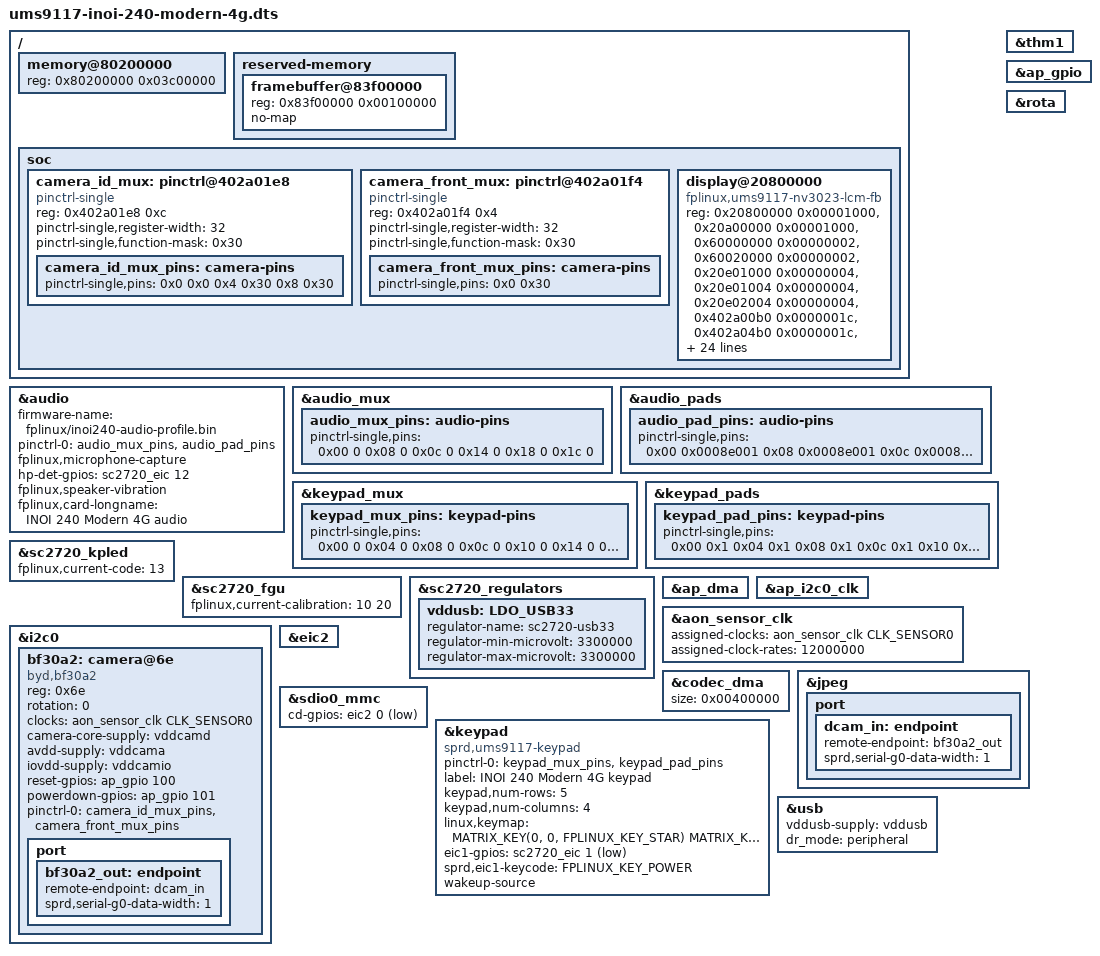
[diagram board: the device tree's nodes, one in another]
// SPDX-License-Identifier: GPL-2.0-only
/dts-v1/;

#include <dt-bindings/input/input.h>
#include <dt-bindings/input/fplinux-keypad.h>
#include <dt-bindings/gpio/gpio.h>
#include <dt-bindings/leds/common.h>
#include "ums9117.dtsi"
#include "ums9117-sc2720.dtsi"
#include "ums9117-musb-cold.dtsi"
#include "fplinux-inoi-240-modern-4g-identity.dtsi"
#include "inoi-240-modern-4g-nand-readonly.dtsi"
#include "inoi-240-modern-4g-bluetooth.dtsi"

/ {
	memory@80200000 {
		device_type = "memory";
		reg = <0x80200000 0x03c00000>;
	};

	reserved-memory {
		#address-cells = <1>;
		#size-cells = <1>;
		ranges;

		framebuffer@83f00000 {
			reg = <0x83f00000 0x00100000>;
			no-map;
		};
	};

	soc {
		camera_id_mux: pinctrl@402a01e8 {
			compatible = "pinctrl-single";
			reg = <0x402a01e8 0xc>;
			#pinctrl-cells = <1>;
			pinctrl-single,register-width = <32>;
			pinctrl-single,function-mask = <0x30>;

			camera_id_mux_pins: camera-pins {
				pinctrl-single,pins = <0x0 0x0 0x4 0x30 0x8 0x30>;
			};
		};

		camera_front_mux: pinctrl@402a01f4 {
			compatible = "pinctrl-single";
			reg = <0x402a01f4 0x4>;
			#pinctrl-cells = <1>;
			pinctrl-single,register-width = <32>;
			pinctrl-single,function-mask = <0x30>;

			camera_front_mux_pins: camera-pins {
				pinctrl-single,pins = <0x0 0x30>;
			};
		};

		display@20800000 {
			compatible = "fplinux,ums9117-nv3023-lcm-fb";
			reg = <0x20800000 0x00001000>,
			      <0x20a00000 0x00001000>,
			      <0x60000000 0x00000002>,
			      <0x60020000 0x00000002>,
			      <0x20e01000 0x00000004>,
			      <0x20e01004 0x00000004>,
			      <0x20e02004 0x00000004>,
			      <0x402a00b0 0x0000001c>,
			      <0x402a04b0 0x0000001c>,
			      <0x402a01f8 0x00000028>,
			      <0x402a05f8 0x00000028>;
			reg-names = "lcdc", "lcm", "lcm-command", "lcm-data",
				    "ap-ahb-gate-set", "ap-ahb-reset-set",
				    "ap-ahb-reset-clear", "pinmux", "pinconf",
				    "pinmux-data", "pinconf-data";
			interrupts = <GIC_SPI 19 IRQ_TYPE_LEVEL_HIGH>;
			interrupt-names = "lcdc-done";
			sprd,aon-apb = <&aon_apb>;
			sprd,pmic = <&sc2720_pmic>;
			memory-region = <&codec_dma>;
			/* fpdoom cmd3025_inoi MCU timing at the 128 MHz AHB clock. */
			sprd,dbi-timing-ns = <50 55 110 20 70 35>;
			/* LCM control pins. */
			sprd,pinmux-offsets = <
				0x000 0x004 0x008 0x00c 0x010 0x014 0x018
			>;
			sprd,pinmux-values = <
				0 0 0x10 0x10 0x10 0x10 0x10
			>;
			sprd,pinconf-offsets = <
				0x000 0x004 0x008 0x00c 0x010 0x014 0x018
			>;
			sprd,pinconf-values = <
				0x00182001 0x00182046 0x00182001
				0x00182004 0x00182004 0x00182004 0x00182004
			>;
			/* Ten DBI data pins, separate from the intervening peripherals. */
			sprd,pinmux-data-offsets = <
				0x00 0x04 0x08 0x0c 0x10 0x14 0x18 0x1c 0x20 0x24
			>;
			sprd,pinmux-data-values = <
				0x10 0x10 0x10 0x10 0x10
				0x10 0x10 0x10 0x10 0x10
			>;
			sprd,pinconf-data-offsets = <
				0x00 0x04 0x08 0x0c 0x10 0x14 0x18 0x1c 0x20 0x24
			>;
			sprd,pinconf-data-values = <
				0x00182004 0x00182004 0x00182004 0x00182004 0x00182004
				0x00182004 0x00182004 0x00182004 0x00182004 0x00182004
			>;
			/* INOI uses RGB WLED channels only; the W channel stays dark. */
			sprd,wled-current-levels = <31 31 31 0>;
			sprd,wled-default-level = <18>;
		};
	};
};

#include "ums9117-ram-session.dtsi"

&audio {
	firmware-name = "fplinux/inoi240-audio-profile.bin";
	pinctrl-names = "audio";
	pinctrl-0 = <&audio_mux_pins &audio_pad_pins>;
	fplinux,microphone-capture;
	hp-det-gpios = <&sc2720_eic 12 GPIO_ACTIVE_HIGH>;
	fplinux,speaker-vibration;
	fplinux,card-longname = "INOI 240 Modern 4G audio";
	status = "okay";
};

&audio_mux {
	audio_mux_pins: audio-pins {
		pinctrl-single,pins = <
			0x00 0 0x08 0 0x0c 0
			0x14 0 0x18 0 0x1c 0
		>;
	};
};

&audio_pads {
	audio_pad_pins: audio-pins {
		pinctrl-single,pins = <
			0x00 0x0008e001 0x08 0x0008e001
			0x0c 0x0008e001 0x14 0x0008e000
			0x18 0x0008e000 0x1c 0x0008e001
		>;
	};
};

&keypad_mux {
	keypad_mux_pins: keypad-pins {
		pinctrl-single,pins = <
			0x00 0 0x04 0 0x08 0 0x0c 0 0x10 0
			0x14 0 0x18 0 0x1c 0 0x20 0 0x24 0
		>;
	};
};

&keypad_pads {
	keypad_pad_pins: keypad-pins {
		pinctrl-single,pins = <
			0x00 0x1 0x04 0x1 0x08 0x1 0x0c 0x1 0x10 0x1
			0x14 0x8a 0x18 0x8a 0x1c 0x8a 0x20 0x8a 0x24 0x8a
		>;
	};
};

&sc2720_kpled {
	fplinux,current-code = <13>;
};

&sc2720_fgu {
	fplinux,current-calibration = <10 20>;
};

&sc2720_regulators {
	vddusb: LDO_USB33 {
		regulator-name = "sc2720-usb33";
		regulator-min-microvolt = <3300000>;
		regulator-max-microvolt = <3300000>;
	};
};

&thm1 {
	status = "okay";
};

&ap_dma {
	status = "okay";
};

&ap_gpio {
	status = "okay";
};

&ap_i2c0_clk {
	status = "okay";
};

&aon_sensor_clk {
	assigned-clocks = <&aon_sensor_clk CLK_SENSOR0>;
	assigned-clock-rates = <12000000>;
	status = "okay";
};

&i2c0 {
	status = "okay";

	bf30a2: camera@6e {
		compatible = "byd,bf30a2";
		reg = <0x6e>;
		rotation = <0>;
		clocks = <&aon_sensor_clk CLK_SENSOR0>;
		clock-names = "xclk";
		camera-core-supply = <&vddcamd>;
		avdd-supply = <&vddcama>;
		iovdd-supply = <&vddcamio>;
		reset-gpios = <&ap_gpio 100 GPIO_ACTIVE_HIGH>;
		powerdown-gpios = <&ap_gpio 101 GPIO_ACTIVE_HIGH>;
		pinctrl-names = "default";
		pinctrl-0 = <&camera_id_mux_pins &camera_front_mux_pins>;

		port {
			bf30a2_out: endpoint {
				remote-endpoint = <&dcam_in>;
				sprd,serial-g0-data-width = <1>;
			};
		};
	};
};

&codec_dma {
	size = <0x00400000>;
};

&rota {
	status = "okay";
};

&jpeg {
	status = "okay";
	port {
		dcam_in: endpoint {
		};
	};
};

&dcam_in {
	remote-endpoint = <&bf30a2_out>;
	sprd,serial-g0-data-width = <1>;
};

&eic2 {
	status = "okay";
};

&sdio0_mmc {
	cd-gpios = <&eic2 0 GPIO_ACTIVE_LOW>;
	status = "okay";
};

&keypad {
	pinctrl-names = "matrix";
	pinctrl-0 = <&keypad_mux_pins &keypad_pad_pins>;
	compatible = "sprd,ums9117-keypad";
	status = "okay";
	label = "INOI 240 Modern 4G keypad";
	keypad,num-rows = <5>;
	keypad,num-columns = <4>;
	linux,keymap = <
		MATRIX_KEY(0, 0, FPLINUX_KEY_STAR)
		MATRIX_KEY(0, 1, FPLINUX_KEY_0)
		MATRIX_KEY(0, 2, FPLINUX_KEY_POUND)
		MATRIX_KEY(0, 3, FPLINUX_KEY_OK)
		MATRIX_KEY(1, 0, FPLINUX_KEY_7)
		MATRIX_KEY(1, 1, FPLINUX_KEY_8)
		MATRIX_KEY(1, 2, FPLINUX_KEY_9)
		MATRIX_KEY(1, 3, FPLINUX_KEY_LEFT)
		MATRIX_KEY(2, 0, FPLINUX_KEY_4)
		MATRIX_KEY(2, 1, FPLINUX_KEY_5)
		MATRIX_KEY(2, 2, FPLINUX_KEY_6)
		MATRIX_KEY(2, 3, FPLINUX_KEY_RIGHT)
		MATRIX_KEY(3, 0, FPLINUX_KEY_1)
		MATRIX_KEY(3, 1, FPLINUX_KEY_2)
		MATRIX_KEY(3, 2, FPLINUX_KEY_3)
		MATRIX_KEY(3, 3, FPLINUX_KEY_DOWN)
		MATRIX_KEY(4, 0, FPLINUX_KEY_SOFT_LEFT)
		MATRIX_KEY(4, 1, FPLINUX_KEY_CALL)
		MATRIX_KEY(4, 2, FPLINUX_KEY_SOFT_RIGHT)
		MATRIX_KEY(4, 3, FPLINUX_KEY_UP)
	>;
	eic1-gpios = <&sc2720_eic 1 GPIO_ACTIVE_LOW>;
	sprd,eic1-keycode = <FPLINUX_KEY_POWER>;
	wakeup-source;
};

&usb {
	vddusb-supply = <&vddusb>;
	dr_mode = "peripheral";
	status = "okay";
};
